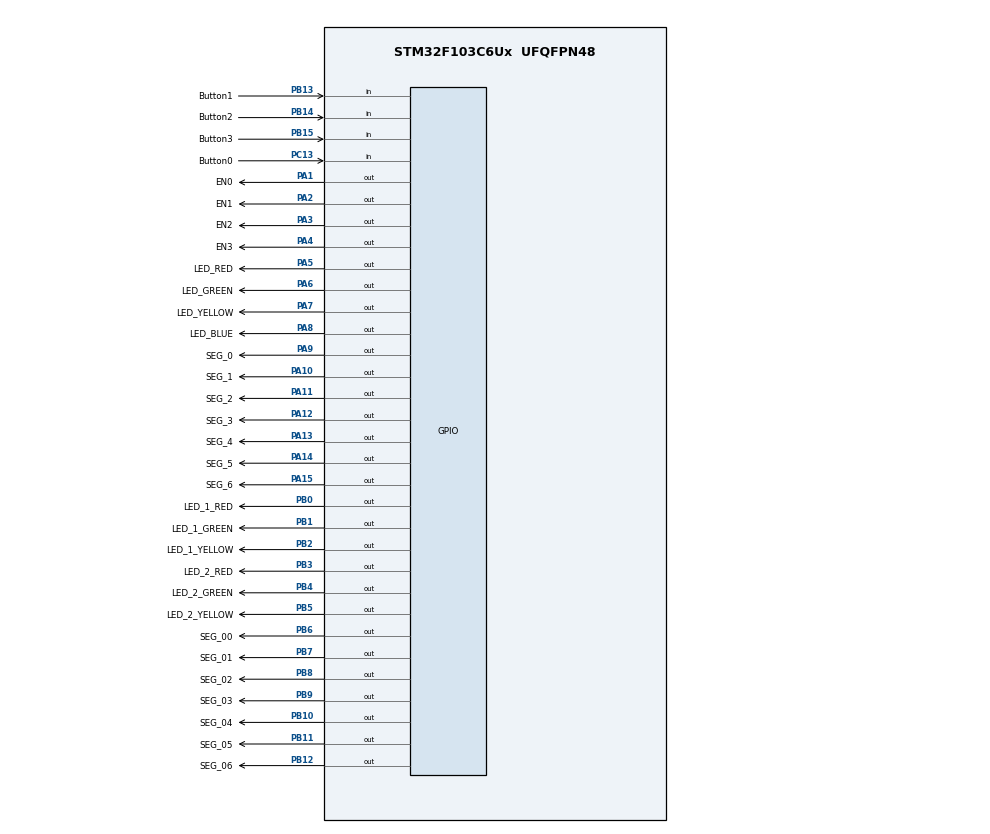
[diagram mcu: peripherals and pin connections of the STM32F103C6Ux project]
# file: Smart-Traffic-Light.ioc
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Mcu.Family=STM32F1
Mcu.Name=STM32F103C6Ux
Mcu.Package=UFQFPN48
NVIC.PriorityGroup=NVIC_PRIORITYGROUP_4
NVIC.TIM2_IRQn=true\:0\:0\:false\:false\:true\:true\:true\:true
PA1.GPIO_Label=EN0
PA1.Signal=GPIO_Output
PA10.GPIO_Label=SEG_1
PA10.Signal=GPIO_Output
PA11.GPIO_Label=SEG_2
PA11.Signal=GPIO_Output
PA12.GPIO_Label=SEG_3
PA12.Signal=GPIO_Output
PA13.GPIO_Label=SEG_4
PA13.GPIO_PuPd=GPIO_NOPULL
PA13.Signal=GPIO_Output
PA14.GPIO_Label=SEG_5
PA14.Signal=GPIO_Output
PA15.GPIO_Label=SEG_6
PA15.Signal=GPIO_Output
PA2.GPIO_Label=EN1
PA2.Signal=GPIO_Output
PA3.GPIO_Label=EN2
PA3.Signal=GPIO_Output
PA4.GPIO_Label=EN3
PA4.Signal=GPIO_Output
PA5.GPIO_Label=LED_RED
PA5.Signal=GPIO_Output
PA6.GPIO_Label=LED_GREEN
PA6.Signal=GPIO_Output
PA7.GPIO_Label=LED_YELLOW
PA7.Signal=GPIO_Output
PA8.GPIO_Label=LED_BLUE
PA8.Signal=GPIO_Output
PA9.GPIO_Label=SEG_0
PA9.Signal=GPIO_Output
PB0.GPIO_Label=LED_1_RED
PB0.Signal=GPIO_Output
PB1.GPIO_Label=LED_1_GREEN
PB1.Signal=GPIO_Output
PB10.GPIO_Label=SEG_04
PB10.Signal=GPIO_Output
PB11.GPIO_Label=SEG_05
PB11.Signal=GPIO_Output
PB12.GPIO_Label=SEG_06
PB12.Signal=GPIO_Output
PB13.GPIO_Label=Button1
PB13.GPIO_PuPd=GPIO_PULLUP
PB13.Signal=GPIO_Input
PB14.GPIO_Label=Button2
PB14.GPIO_PuPd=GPIO_PULLUP
PB14.Signal=GPIO_Input
PB15.GPIO_Label=Button3
PB15.GPIO_PuPd=GPIO_PULLUP
PB15.Signal=GPIO_Input
PB2.GPIO_Label=LED_1_YELLOW
PB2.Signal=GPIO_Output
PB3.GPIO_Label=LED_2_RED
PB3.Signal=GPIO_Output
PB4.GPIO_Label=LED_2_GREEN
PB4.Signal=GPIO_Output
PB5.GPIO_Label=LED_2_YELLOW
PB5.Signal=GPIO_Output
PB6.GPIO_Label=SEG_00
PB6.Signal=GPIO_Output
PB7.GPIO_Label=SEG_01
PB7.Signal=GPIO_Output
PB8.GPIO_Label=SEG_02
PB8.Signal=GPIO_Output
PB9.GPIO_Label=SEG_03
PB9.Signal=GPIO_Output
PC13-TAMPER-RTC.GPIO_Label=Button0
PC13-TAMPER-RTC.GPIO_PuPd=GPIO_PULLUP
PC13-TAMPER-RTC.Signal=GPIO_Input
ProjectManager.HeapSize=0x200
ProjectManager.StackSize=0x400
ProjectManager.TargetToolchain=STM32CubeIDE
RCC.APB1Freq_Value=8000000
RCC.APB2Freq_Value=8000000
TIM2.Period=9
TIM2.Prescaler=7999
VP_SYS_VS_ND.Mode=No_Debug
VP_TIM2_VS_ClockSourceINT.Mode=Internal
board=custom

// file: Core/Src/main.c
/* USER CODE BEGIN Header */
/**
  ******************************************************************************
  * @file           : main.c
  * @brief          : Main program body
  ******************************************************************************
  * @attention
  *
  * <h2><center>&copy; Copyright (c) 2024 STMicroelectronics.
  * All rights reserved.</center></h2>
  *
  * This software component is licensed by ST under BSD 3-Clause license,
  * the "License"; You may not use this file except in compliance with the
  * License. You may obtain a copy of the License at:
  *                        opensource.org/licenses/BSD-3-Clause
  *
  ******************************************************************************
  */
/* USER CODE END Header */
#include "main.h"

/* USER CODE BEGIN Includes */
#include "software_timer.h"
#include "scheduler.h"
#include  "button.h"
#include "fsm_automatic.h"
#include "fsm_manual.h"
#include "fsm_setting.h"
#include "fsm_button.h"
/* USER CODE END Includes */

TIM_HandleTypeDef htim2;

void SystemClock_Config(void);
static void MX_GPIO_Init(void);
static void MX_TIM2_Init(void);

/* USER CODE BEGIN 0 */
void Led_Toggle(){
		HAL_GPIO_TogglePin(LED_RED_GPIO_Port, LED_RED_Pin);
}

void dispModeWrapper(){
	dispMode(mode);
}
/* USER CODE END 0 */

int main(void)
{

  /* MCU Configuration--------------------------------------------------------*/

  /* Reset of all peripherals, Initializes the Flash interface and the Systick. */
  HAL_Init();

  /* Configure the system clock */
  SystemClock_Config();

  /* Initialize all configured peripherals */
  MX_GPIO_Init();
  MX_TIM2_Init();
  /* USER CODE BEGIN 2 */
  HAL_TIM_Base_Start_IT(&htim2);
  /* USER CODE END 2 */

  /* Infinite loop */
//  /* USER CODE BEGIN WHILE */
//  setTimer0(100);
//  setTimer1(100);
//  setTimer2(100);
//  setTimer3(100);
//  setTimerLed(100);
  // Start Button
  	SCH_Add_Task(getKey1Input, 0, 10);
  	SCH_Add_Task(getKey2Input, 0, 10);
  	SCH_Add_Task(getKey3Input, 0, 10);
  // End Button

  	// Start Display Led
  	SCH_Add_Task(dispModeWrapper, 0, 10);
  	SCH_Add_Task(updateClock, 0, 10);
  	// End Display Led

  	SCH_Add_Task(fsm_automatic_run, 0, 10);
  	SCH_Add_Task(fsm_manual_run, 0, 10);
  	SCH_Add_Task(fsm_setting_run, 0, 10);
//  	  	  SCH_Add_Task(Led_Toggle, 0, 100);
  while (1)
  {
	  SCH_Dispatch_Tasks();
	  if (timer0_flag == 1){
		  HAL_GPIO_TogglePin(LED_RED_GPIO_Port, LED_RED_Pin);
		  setTimer0(1000);
	  }
//
//		dispMode(mode);
//		fsm_automatic_run();
//		fsm_manual_run();
//		fsm_setting_run();
//		updateClock();

    /* USER CODE END WHILE */

  }
}

void SystemClock_Config(void)
{
  RCC_OscInitTypeDef RCC_OscInitStruct = {0};
  RCC_ClkInitTypeDef RCC_ClkInitStruct = {0};

  /** Initializes the RCC Oscillators according to the specified parameters
  * in the RCC_OscInitTypeDef structure.
  */
  RCC_OscInitStruct.OscillatorType = RCC_OSCILLATORTYPE_HSI;
  RCC_OscInitStruct.HSIState = RCC_HSI_ON;
  RCC_OscInitStruct.HSICalibrationValue = RCC_HSICALIBRATION_DEFAULT;
  RCC_OscInitStruct.PLL.PLLState = RCC_PLL_NONE;
  if (HAL_RCC_OscConfig(&RCC_OscInitStruct) != HAL_OK)
  {
    Error_Handler();
  }
  /** Initializes the CPU, AHB and APB buses clocks
  */
  RCC_ClkInitStruct.ClockType = RCC_CLOCKTYPE_HCLK|RCC_CLOCKTYPE_SYSCLK
                              |RCC_CLOCKTYPE_PCLK1|RCC_CLOCKTYPE_PCLK2;
  RCC_ClkInitStruct.SYSCLKSource = RCC_SYSCLKSOURCE_HSI;
  RCC_ClkInitStruct.AHBCLKDivider = RCC_SYSCLK_DIV1;
  RCC_ClkInitStruct.APB1CLKDivider = RCC_HCLK_DIV1;
  RCC_ClkInitStruct.APB2CLKDivider = RCC_HCLK_DIV1;

  if (HAL_RCC_ClockConfig(&RCC_ClkInitStruct, FLASH_LATENCY_0) != HAL_OK)
  {
    Error_Handler();
  }
}

static void MX_TIM2_Init(void)
{

  TIM_ClockConfigTypeDef sClockSourceConfig = {0};
  TIM_MasterConfigTypeDef sMasterConfig = {0};

  htim2.Instance = TIM2;
  htim2.Init.Prescaler = 7999;
  htim2.Init.CounterMode = TIM_COUNTERMODE_UP;
  htim2.Init.Period = 9;
  htim2.Init.ClockDivision = TIM_CLOCKDIVISION_DIV1;
  htim2.Init.AutoReloadPreload = TIM_AUTORELOAD_PRELOAD_DISABLE;
  if (HAL_TIM_Base_Init(&htim2) != HAL_OK)
  {
    Error_Handler();
  }
  sClockSourceConfig.ClockSource = TIM_CLOCKSOURCE_INTERNAL;
  if (HAL_TIM_ConfigClockSource(&htim2, &sClockSourceConfig) != HAL_OK)
  {
    Error_Handler();
  }
  sMasterConfig.MasterOutputTrigger = TIM_TRGO_RESET;
  sMasterConfig.MasterSlaveMode = TIM_MASTERSLAVEMODE_DISABLE;
  if (HAL_TIMEx_MasterConfigSynchronization(&htim2, &sMasterConfig) != HAL_OK)
  {
    Error_Handler();
  }

}

static void MX_GPIO_Init(void)
{
  GPIO_InitTypeDef GPIO_InitStruct = {0};

  /* GPIO Ports Clock Enable */
  __HAL_RCC_GPIOC_CLK_ENABLE();
  __HAL_RCC_GPIOA_CLK_ENABLE();
  __HAL_RCC_GPIOB_CLK_ENABLE();

  /*Configure GPIO pin Output Level */
  HAL_GPIO_WritePin(GPIOA, EN0_Pin|EN1_Pin|EN2_Pin|EN3_Pin
                          |LED_RED_Pin|LED_GREEN_Pin|LED_YELLOW_Pin|LED_BLUE_Pin
                          |SEG_0_Pin|SEG_1_Pin|SEG_2_Pin|SEG_3_Pin
                          |SEG_4_Pin|SEG_5_Pin|SEG_6_Pin, GPIO_PIN_RESET);

  /*Configure GPIO pin Output Level */
  HAL_GPIO_WritePin(GPIOB, LED_1_RED_Pin|LED_1_GREEN_Pin|LED_1_YELLOW_Pin|SEG_04_Pin
                          |SEG_05_Pin|SEG_06_Pin|LED_2_RED_Pin|LED_2_GREEN_Pin
                          |LED_2_YELLOW_Pin|SEG_00_Pin|SEG_01_Pin|SEG_02_Pin
                          |SEG_03_Pin, GPIO_PIN_RESET);

  /*Configure GPIO pin : Button0_Pin */
  GPIO_InitStruct.Pin = Button0_Pin;
  GPIO_InitStruct.Mode = GPIO_MODE_INPUT;
  GPIO_InitStruct.Pull = GPIO_PULLUP;
  HAL_GPIO_Init(Button0_GPIO_Port, &GPIO_InitStruct);

  /*Configure GPIO pins : EN0_Pin EN1_Pin EN2_Pin EN3_Pin
                           LED_RED_Pin LED_GREEN_Pin LED_YELLOW_Pin LED_BLUE_Pin
                           SEG_0_Pin SEG_1_Pin SEG_2_Pin SEG_3_Pin
                           SEG_4_Pin SEG_5_Pin SEG_6_Pin */
  GPIO_InitStruct.Pin = EN0_Pin|EN1_Pin|EN2_Pin|EN3_Pin
                          |LED_RED_Pin|LED_GREEN_Pin|LED_YELLOW_Pin|LED_BLUE_Pin
                          |SEG_0_Pin|SEG_1_Pin|SEG_2_Pin|SEG_3_Pin
                          |SEG_4_Pin|SEG_5_Pin|SEG_6_Pin;
  GPIO_InitStruct.Mode = GPIO_MODE_OUTPUT_PP;
  GPIO_InitStruct.Pull = GPIO_NOPULL;
  GPIO_InitStruct.Speed = GPIO_SPEED_FREQ_LOW;
  HAL_GPIO_Init(GPIOA, &GPIO_InitStruct);

  /*Configure GPIO pins : LED_1_RED_Pin LED_1_GREEN_Pin LED_1_YELLOW_Pin SEG_04_Pin
                           SEG_05_Pin SEG_06_Pin LED_2_RED_Pin LED_2_GREEN_Pin
                           LED_2_YELLOW_Pin SEG_00_Pin SEG_01_Pin SEG_02_Pin
                           SEG_03_Pin */
  GPIO_InitStruct.Pin = LED_1_RED_Pin|LED_1_GREEN_Pin|LED_1_YELLOW_Pin|SEG_04_Pin
                          |SEG_05_Pin|SEG_06_Pin|LED_2_RED_Pin|LED_2_GREEN_Pin
                          |LED_2_YELLOW_Pin|SEG_00_Pin|SEG_01_Pin|SEG_02_Pin
                          |SEG_03_Pin;
  GPIO_InitStruct.Mode = GPIO_MODE_OUTPUT_PP;
  GPIO_InitStruct.Pull = GPIO_NOPULL;
  GPIO_InitStruct.Speed = GPIO_SPEED_FREQ_LOW;
  HAL_GPIO_Init(GPIOB, &GPIO_InitStruct);

  /*Configure GPIO pins : Button1_Pin Button2_Pin Button3_Pin */
  GPIO_InitStruct.Pin = Button1_Pin|Button2_Pin|Button3_Pin;
  GPIO_InitStruct.Mode = GPIO_MODE_INPUT;
  GPIO_InitStruct.Pull = GPIO_PULLUP;
  HAL_GPIO_Init(GPIOB, &GPIO_InitStruct);

}

/* USER CODE BEGIN 4 */
void HAL_TIM_PeriodElapsedCallback(TIM_HandleTypeDef *htim){
	SCH_Update();
//	timerRun();
}
/* USER CODE END 4 */

void Error_Handler(void)
{
  __disable_irq();
  while (1)
  {
  }
}

/************************ (C) COPYRIGHT STMicroelectronics *****END OF FILE****/
